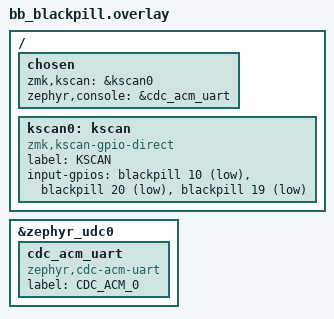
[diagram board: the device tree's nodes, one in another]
/*
 * Copyright (c) 2022 The ZMK Contributors
 *
 * SPDX-License-Identifier: MIT
 */

/ {
	chosen {
		zmk,kscan = &kscan0;
		zephyr,console = &cdc_acm_uart;
	};

	kscan0: kscan {
		compatible = "zmk,kscan-gpio-direct";

		label = "KSCAN";

		input-gpios
			// Blackpill onboard user key button on pin 10
			= <&blackpill 10 (GPIO_ACTIVE_LOW | GPIO_PULL_UP)>

			// Switches connected directly to gpio pins
			, <&blackpill 20 (GPIO_ACTIVE_LOW | GPIO_PULL_UP)>
			, <&blackpill 19 (GPIO_ACTIVE_LOW | GPIO_PULL_UP)>
			;

	};

};

&zephyr_udc0 {
    cdc_acm_uart: cdc_acm_uart {
        compatible = "zephyr,cdc-acm-uart";
        label = "CDC_ACM_0";
    };
};
